AUTOSAR XML (schema 4-0-3)
package /ArPackage_CDD_Router/BswImplementations
  4 x bsw implementation, all with vendor-id=76, ar-release-version=4.0.3:
    BswImplementation_CDD_RouterIF: sw-version=2.3.5, swc-bsw-mapping=SwcBswMapping_CDD_RouterIF, behavior=BswInternalBehavior_CDD_RouterIF
    BswImplementation_CDD_RouterTP: sw-version=2.3.5, behavior=BswInternalBehavior_CDD_RouterTP
    BswImplementation_CDD_IPC_IF: sw-version=2.3.0, behavior=BswInternalBehavior_CDD_IPC_IF
    BswImplementation_CDD_IPC_TP: sw-version=2.3.0, behavior=BswInternalBehavior_CDD_IPC_TP
package /ArPackage_CDD_Router/BswModuleDescriptions
  4 x bsw module description:
    CDD_RouterIF: module-id=98
      bsw internal behavior BswInternalBehavior_CDD_RouterIF
        5 x bsw called entity:
          CDD_RouterIF_CancelTransmit: implemented-entry=CDD_RouterIF_CancelTransmit
          CDD_RouterIF_RxIndication: implemented-entry=CDD_RouterIF_RxIndication
          CDD_RouterIF_Transmit: implemented-entry=CDD_RouterIF_Transmit
          CDD_RouterIF_CanTpTransmit: implemented-entry=CDD_RouterIF_CanTpTransmit
          CDD_RouterIF_TxConfirmation: implemented-entry=CDD_RouterIF_TxConfirmation
    CDD_RouterTP: module-id=99
      bsw internal behavior BswInternalBehavior_CDD_RouterTP
        bsw called entity CDD_RouterTP_CancelReceive: implemented-entry=CDD_RouterTP_CancelReceive
        bsw called entity CDD_RouterTP_CancelTransmit: implemented-entry=CDD_RouterTP_CancelTransmit
        bsw called entity CDD_RouterTP_Transmit: implemented-entry=CDD_RouterTP_Transmit
    CDD_IPC_TP: module-id=97
      bsw internal behavior BswInternalBehavior_CDD_IPC_TP
        bsw called entity CDD_IPC_TP_Transmit: implemented-entry=CDD_IPC_TP_Transmit
    CDD_IPC_IF: module-id=96
      bsw internal behavior BswInternalBehavior_CDD_IPC_IF
        bsw called entity CDD_IPC_RxIndication: implemented-entry=CDD_IPC_RxIndication
        bsw called entity CDD_IPC_IF_Transmit: implemented-entry=CDD_IPC_IF_Transmit
package /ArPackage_CDD_Router/BswModuleEntrys
  13 x bsw module entry, all with is-reentrant=false, is-synchronous=true, call-type=REGULAR, sw-service-impl-policy=STANDARD:
    CDD_RouterIF_RxIndication: service-id=0, execution-context=UNSPECIFIED
    CDD_RouterTP_Transmit: service-id=0, execution-context=TASK
    CDD_RouterTP_CancelTransmit: service-id=2, execution-context=TASK
    CDD_RouterTP_CancelReceive: service-id=1, execution-context=TASK
    CDD_RouterIF_TxConfirmation: service-id=3, execution-context=UNSPECIFIED
    CDD_RouterIF_Transmit: service-id=2, execution-context=UNSPECIFIED
    CDD_RouterIF_CanTpTransmit: service-id=6, execution-context=UNSPECIFIED
    CDD_RouterIF_CancelTransmit: service-id=1, execution-context=UNSPECIFIED
    CDD_RouterIF_SoAdIfTxConfirmation: service-id=4, execution-context=UNSPECIFIED
    CDD_RouterIF_SoAdIfRxIndication: service-id=5, execution-context=UNSPECIFIED
    CDD_IPC_RxIndication: service-id=0, execution-context=UNSPECIFIED
    CDD_IPC_TP_Transmit: service-id=0, execution-context=TASK
    CDD_IPC_IF_Transmit: service-id=1, execution-context=UNSPECIFIED
package /ArPackage_CDD_Router/ClientServerInterfaces
  client server interface CDD_Router_ClientServerInterface: is-service=true
    operation CDD_RouterRequestMode
      arg RoutingID: type=uint16, direction=IN, server-argument-impl-policy=USE-ARGUMENT-TYPE
      arg RoutingStatus: type=uint8, direction=IN, server-argument-impl-policy=USE-ARGUMENT-TYPE
package /ArPackage_CDD_Router/ComplexDeviceDriverSwComponentType
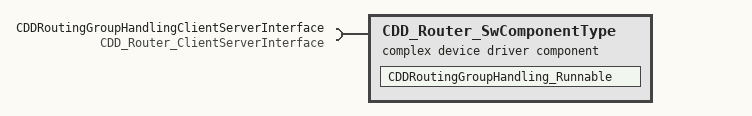
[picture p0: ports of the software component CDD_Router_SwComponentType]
  complex device driver sw component type CDD_Router_SwComponentType
    require port CDDRoutingGroupHandlingClientServerInterface: client-com-spec=CDD_RouterRequestMode, required-interface=CDD_Router_ClientServerInterface
    behavior SwcIB_CDDRouting
      runnable CDDRoutingGroupHandling_Runnable: symbol=CDD_RouterIF_RxIndication
        sync call SSCP_CDDRoutingGroupHandling_Runnable_CDDRoutingGroupHandlingClientServerInterface_CDD_RouterRequestMode: operation=CDDRoutingGroupHandlingClientServerInterface.CDD_RouterRequestMode
  swc implementation SwcImplementation_CDD_Router: programming-language=C, sw-version=2.3.0, swc-bsw-mapping=SwcBswMapping_CDD_RouterIF, vendor-id=76, behavior=SwcIB_CDDRouting
package /ArPackage_CDD_Router/SwcBswMapping
  swc bsw mapping SwcBswMapping_CDD_RouterIF: bsw-behavior=BswInternalBehavior_CDD_RouterIF, swc-bsw-runnable-mapping{bsw-entity=CDD_RouterIF_RxIndication, swc-runnable=CDDRoutingGroupHandling_Runnable}, swc-behavior=SwcIB_CDDRouting
